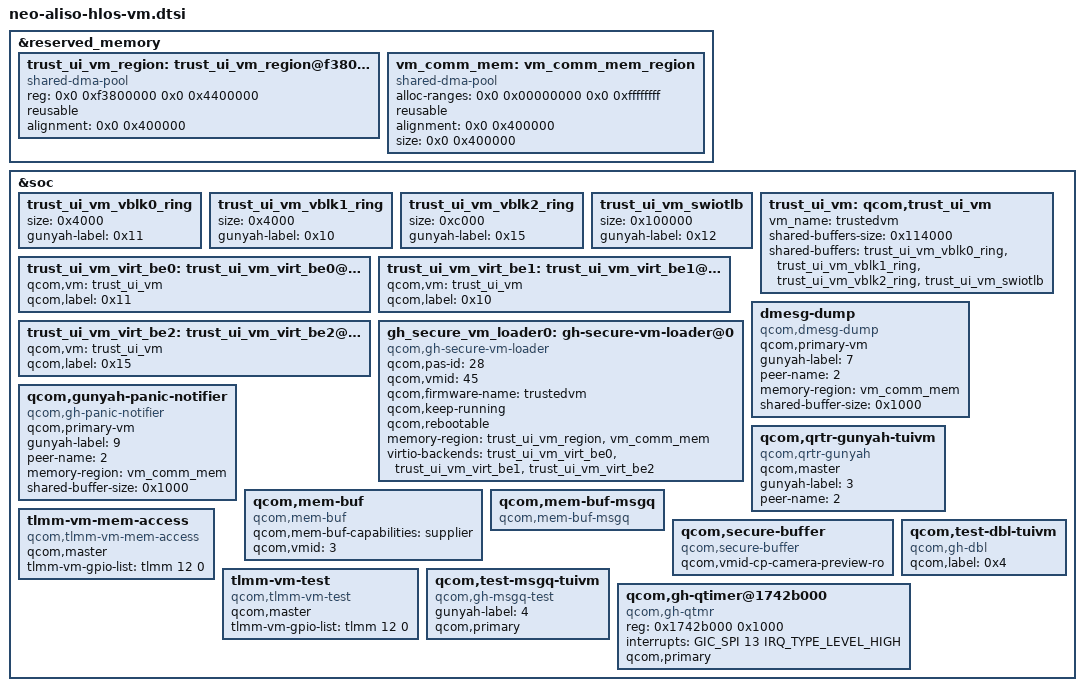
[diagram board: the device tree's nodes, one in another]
&reserved_memory { /* UPDATE: may be moved to neo-aliso-reserved-memory.dtsi */

	trust_ui_vm_region: trust_ui_vm_region@f3800000 {
		compatible = "shared-dma-pool";
		reg = <0x0 0xf3800000 0x0 0x4400000>;
		reusable;
		alignment = <0x0 0x400000>;
	};

	vm_comm_mem: vm_comm_mem_region {
		compatible = "shared-dma-pool";
		alloc-ranges = <0x0 0x00000000 0x0 0xffffffff>;
		reusable;
		alignment = <0x0 0x400000>;
		size = <0x0 0x400000>;
	};
};

/*
 * TUIVM is supported only on Aliso variant of Neo SoC.
 * Add device nodes of HLOS VM aka Primary VM here.
 */
&soc {
	trust_ui_vm_vblk0_ring: trust_ui_vm_vblk0_ring {
		size = <0x4000>;
		gunyah-label = <0x11>;
	};

	trust_ui_vm_vblk1_ring: trust_ui_vm_vblk1_ring {
		size = <0x4000>;
		gunyah-label = <0x10>;
	};

	trust_ui_vm_vblk2_ring: trust_ui_vm_vblk2_ring {
		size = <0xc000>;
		gunyah-label = <0x15>;
	};

	trust_ui_vm_swiotlb: trust_ui_vm_swiotlb {
		size = <0x100000>;
		gunyah-label = <0x12>;
	};

	trust_ui_vm: qcom,trust_ui_vm {
		vm_name = "trustedvm";
		shared-buffers-size = <0x114000>;
		shared-buffers = <&trust_ui_vm_vblk0_ring &trust_ui_vm_vblk1_ring &trust_ui_vm_vblk2_ring &trust_ui_vm_swiotlb>;
	};

	trust_ui_vm_virt_be0: trust_ui_vm_virt_be0@11 {
		qcom,vm = <&trust_ui_vm>;
		qcom,label = <0x11>;
	};

	trust_ui_vm_virt_be1: trust_ui_vm_virt_be1@10 {
		qcom,vm = <&trust_ui_vm>;
		qcom,label = <0x10>;
	};

	trust_ui_vm_virt_be2: trust_ui_vm_virt_be2@15 {
		qcom,vm = <&trust_ui_vm>;
		qcom,label = <0x15>;
	};

	gh_secure_vm_loader0: gh-secure-vm-loader@0 {
		compatible = "qcom,gh-secure-vm-loader";
		qcom,pas-id = <28>;
		qcom,vmid = <45>;
		qcom,firmware-name = "trustedvm";
		qcom,keep-running;
		qcom,rebootable;
		memory-region = <&trust_ui_vm_region &vm_comm_mem>;
		virtio-backends = <&trust_ui_vm_virt_be0 &trust_ui_vm_virt_be1 &trust_ui_vm_virt_be2>;
	};

	dmesg-dump {
		compatible = "qcom,dmesg-dump";
		qcom,primary-vm;
		gunyah-label = <7>;
		peer-name = <2>;
		memory-region = <&vm_comm_mem>;
		shared-buffer-size = <0x1000>;
	};

	qcom,gunyah-panic-notifier {
		compatible = "qcom,gh-panic-notifier";
		qcom,primary-vm;
		gunyah-label = <9>;
		peer-name = <2>;
		memory-region = <&vm_comm_mem>;
		shared-buffer-size = <0x1000>;
	};

	qcom,qrtr-gunyah-tuivm {
		compatible = "qcom,qrtr-gunyah";
		qcom,master;
		gunyah-label = <3>;
		peer-name = <2>;
	};

	qcom,mem-buf {
		compatible = "qcom,mem-buf";
		qcom,mem-buf-capabilities = "supplier";
		qcom,vmid = <3>;
	};

	qcom,mem-buf-msgq {
		compatible = "qcom,mem-buf-msgq";
	};

	qcom,secure-buffer {
		compatible = "qcom,secure-buffer";
		qcom,vmid-cp-camera-preview-ro;
	};

	tlmm-vm-mem-access {
		compatible = "qcom,tlmm-vm-mem-access";
		qcom,master;
		tlmm-vm-gpio-list = <&tlmm 12 0>;
	};

	tlmm-vm-test {
		compatible = "qcom,tlmm-vm-test";
		qcom,master;
		tlmm-vm-gpio-list = <&tlmm 12 0>;
	};

	qcom,test-dbl-tuivm {
		compatible = "qcom,gh-dbl";
		qcom,label = <0x4>;
	};

	qcom,test-msgq-tuivm {
		compatible = "qcom,gh-msgq-test";
		gunyah-label = <4>;
		qcom,primary;
	};

	qcom,gh-qtimer@1742b000 {
		compatible = "qcom,gh-qtmr";
		reg = <0x1742b000 0x1000>;
		reg-names = "qtmr-base";
		interrupts = <GIC_SPI 13 IRQ_TYPE_LEVEL_HIGH>;
		interrupt-names = "qcom,qtmr-intr";
		qcom,primary;
	};
};
